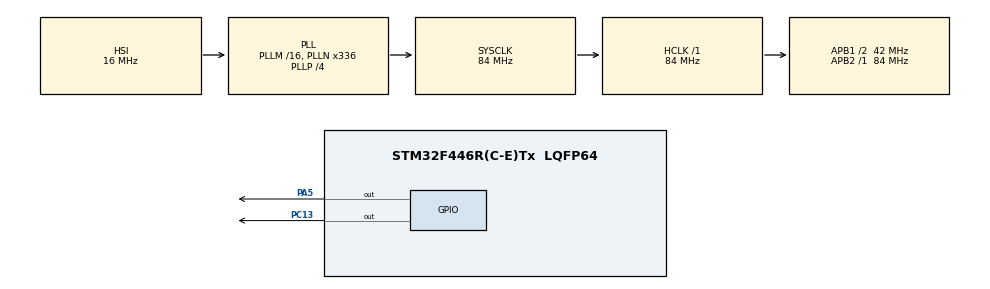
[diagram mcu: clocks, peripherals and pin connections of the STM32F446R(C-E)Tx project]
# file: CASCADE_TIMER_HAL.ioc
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Mcu.Family=STM32F4
Mcu.Name=STM32F446R(C-E)Tx
Mcu.Package=LQFP64
NVIC.PriorityGroup=NVIC_PRIORITYGROUP_0
NVIC.TIM4_IRQn=true\:0\:0\:false\:false\:true\:true\:true\:true
PA13.GPIO_Label=TMS
PA13.Mode=Serial_Wire
PA13.Signal=SYS_JTMS-SWDIO
PA14.GPIO_Label=TCK
PA14.Mode=Serial_Wire
PA14.Signal=SYS_JTCK-SWCLK
PA5.Signal=GPIO_Output
PB3.GPIO_Label=SWO
PB3.Signal=SYS_JTDO-SWO
PC13.Signal=GPIO_Output
PC14-OSC32_IN.Mode=LSE-External-Oscillator
PC14-OSC32_IN.Signal=RCC_OSC32_IN
PC15-OSC32_OUT.Mode=LSE-External-Oscillator
PC15-OSC32_OUT.Signal=RCC_OSC32_OUT
PH0-OSC_IN.Mode=HSE-External-Oscillator
PH0-OSC_IN.Signal=RCC_OSC_IN
PH1-OSC_OUT.Mode=HSE-External-Oscillator
PH1-OSC_OUT.Signal=RCC_OSC_OUT
ProjectManager.HeapSize=0x200
ProjectManager.StackSize=0x400
ProjectManager.TargetToolchain=STM32CubeIDE
RCC.48MHZClocksFreq_Value=84000000
RCC.AHBFreq_Value=84000000
RCC.APB1CLKDivider=RCC_HCLK_DIV2
RCC.APB1Freq_Value=42000000
RCC.APB1TimFreq_Value=84000000
RCC.APB2Freq_Value=84000000
RCC.APB2TimFreq_Value=84000000
RCC.CortexFreq_Value=84000000
RCC.FLatency-AdvancedSettings=FLASH_LATENCY_2
RCC.HCLKFreq_Value=84000000
RCC.HSE_VALUE=8000000
RCC.HSI_VALUE=16000000
RCC.PLLN=336
RCC.PLLP=RCC_PLLP_DIV4
RCC.SYSCLKFreq_VALUE=84000000
RCC.SYSCLKSource=RCC_SYSCLKSOURCE_PLLCLK
RCC.USBFreq_Value=168000000
RCC.VCOOutputFreq_Value=336000000
TIM3.Period=999
TIM3.Prescaler=15999
TIM3.TIM_MasterOutputTrigger=TIM_TRGO_UPDATE
TIM3.TIM_MasterSlaveMode=TIM_MASTERSLAVEMODE_ENABLE
TIM4.AutoReloadPreload=TIM_AUTORELOAD_PRELOAD_DISABLE
TIM4.Period=9
TIM4.TIM_MasterSlaveMode=TIM_MASTERSLAVEMODE_ENABLE
VP_TIM3_VS_ClockSourceINT.Mode=Internal
VP_TIM4_VS_ClockSourceITR.Mode=TriggerSource_ITR2
VP_TIM4_VS_ControllerModeClock.Mode=Clock Mode
board=NUCLEO-F446RE

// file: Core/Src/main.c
/* USER CODE BEGIN Header */
/**
  ******************************************************************************
  * @file           : main.c
  * @brief          : Main program body
  ******************************************************************************
  * @attention
  *
  * Copyright (c) 2025 STMicroelectronics.
  * All rights reserved.
  *
  * This software is licensed under terms that can be found in the LICENSE file
  * in the root directory of this software component.
  * If no LICENSE file comes with this software, it is provided AS-IS.
  *
  ******************************************************************************
  */
/* USER CODE END Header */
#include "main.h"

TIM_HandleTypeDef htim3;
TIM_HandleTypeDef htim4;

void SystemClock_Config(void);
static void MX_GPIO_Init(void);
static void MX_TIM3_Init(void);
static void MX_TIM4_Init(void);

/* USER CODE BEGIN 0 */
void HAL_TIM_PeriodElapsedCallback(TIM_HandleTypeDef *htim)
{
    if (htim->Instance == TIM4)
    {
    	 HAL_GPIO_TogglePin(GPIOA, GPIO_PIN_5);
    }
}

/* USER CODE END 0 */

int main(void)
{

  /* MCU Configuration--------------------------------------------------------*/

  /* Reset of all peripherals, Initializes the Flash interface and the Systick. */
  HAL_Init();

  /* Configure the system clock */
  SystemClock_Config();

  /* Initialize all configured peripherals */
  MX_GPIO_Init();
  MX_TIM3_Init();
  MX_TIM4_Init();
  /* USER CODE BEGIN 2 */
  HAL_TIM_Base_Start(&htim3);
  HAL_Delay(1000);  // <-- Give time for TIM3 to generate TRGO
  HAL_TIM_Base_Start_IT(&htim4);
  /* USER CODE END 2 */

  /* Infinite loop */
  while (1)
  {

  }
}

void SystemClock_Config(void)
{
  RCC_OscInitTypeDef RCC_OscInitStruct = {0};
  RCC_ClkInitTypeDef RCC_ClkInitStruct = {0};

  /** Configure the main internal regulator output voltage
  */
  __HAL_RCC_PWR_CLK_ENABLE();
  __HAL_PWR_VOLTAGESCALING_CONFIG(PWR_REGULATOR_VOLTAGE_SCALE3);

  /** Initializes the RCC Oscillators according to the specified parameters
  * in the RCC_OscInitTypeDef structure.
  */
  RCC_OscInitStruct.OscillatorType = RCC_OSCILLATORTYPE_HSI;
  RCC_OscInitStruct.HSIState = RCC_HSI_ON;
  RCC_OscInitStruct.HSICalibrationValue = RCC_HSICALIBRATION_DEFAULT;
  RCC_OscInitStruct.PLL.PLLState = RCC_PLL_ON;
  RCC_OscInitStruct.PLL.PLLSource = RCC_PLLSOURCE_HSI;
  RCC_OscInitStruct.PLL.PLLM = 16;
  RCC_OscInitStruct.PLL.PLLN = 336;
  RCC_OscInitStruct.PLL.PLLP = RCC_PLLP_DIV4;
  RCC_OscInitStruct.PLL.PLLQ = 2;
  RCC_OscInitStruct.PLL.PLLR = 2;
  if (HAL_RCC_OscConfig(&RCC_OscInitStruct) != HAL_OK)
  {
    Error_Handler();
  }

  /** Initializes the CPU, AHB and APB buses clocks
  */
  RCC_ClkInitStruct.ClockType = RCC_CLOCKTYPE_HCLK|RCC_CLOCKTYPE_SYSCLK
                              |RCC_CLOCKTYPE_PCLK1|RCC_CLOCKTYPE_PCLK2;
  RCC_ClkInitStruct.SYSCLKSource = RCC_SYSCLKSOURCE_PLLCLK;
  RCC_ClkInitStruct.AHBCLKDivider = RCC_SYSCLK_DIV1;
  RCC_ClkInitStruct.APB1CLKDivider = RCC_HCLK_DIV2;
  RCC_ClkInitStruct.APB2CLKDivider = RCC_HCLK_DIV1;

  if (HAL_RCC_ClockConfig(&RCC_ClkInitStruct, FLASH_LATENCY_2) != HAL_OK)
  {
    Error_Handler();
  }
}

static void MX_TIM3_Init(void)
{

  TIM_ClockConfigTypeDef sClockSourceConfig = {0};
  TIM_MasterConfigTypeDef sMasterConfig = {0};

  htim3.Instance = TIM3;
  htim3.Init.Prescaler = 15999;
  htim3.Init.CounterMode = TIM_COUNTERMODE_UP;
  htim3.Init.Period = 999;
  htim3.Init.ClockDivision = TIM_CLOCKDIVISION_DIV1;
  htim3.Init.AutoReloadPreload = TIM_AUTORELOAD_PRELOAD_DISABLE;
  if (HAL_TIM_Base_Init(&htim3) != HAL_OK)
  {
    Error_Handler();
  }
  sClockSourceConfig.ClockSource = TIM_CLOCKSOURCE_INTERNAL;
  if (HAL_TIM_ConfigClockSource(&htim3, &sClockSourceConfig) != HAL_OK)
  {
    Error_Handler();
  }
  sMasterConfig.MasterOutputTrigger = TIM_TRGO_UPDATE;
  sMasterConfig.MasterSlaveMode = TIM_MASTERSLAVEMODE_ENABLE;
  if (HAL_TIMEx_MasterConfigSynchronization(&htim3, &sMasterConfig) != HAL_OK)
  {
    Error_Handler();
  }

}

static void MX_TIM4_Init(void)
{

  TIM_SlaveConfigTypeDef sSlaveConfig = {0};
  TIM_MasterConfigTypeDef sMasterConfig = {0};

  htim4.Instance = TIM4;
  htim4.Init.Prescaler = 0;
  htim4.Init.CounterMode = TIM_COUNTERMODE_UP;
  htim4.Init.Period = 9;
  htim4.Init.ClockDivision = TIM_CLOCKDIVISION_DIV1;
  htim4.Init.AutoReloadPreload = TIM_AUTORELOAD_PRELOAD_DISABLE;
  if (HAL_TIM_Base_Init(&htim4) != HAL_OK)
  {
    Error_Handler();
  }
  sSlaveConfig.SlaveMode = TIM_SLAVEMODE_EXTERNAL1;
  sSlaveConfig.InputTrigger = TIM_TS_ITR2;
  if (HAL_TIM_SlaveConfigSynchro(&htim4, &sSlaveConfig) != HAL_OK)
  {
    Error_Handler();
  }
  sMasterConfig.MasterOutputTrigger = TIM_TRGO_RESET;
  sMasterConfig.MasterSlaveMode = TIM_MASTERSLAVEMODE_ENABLE;
  if (HAL_TIMEx_MasterConfigSynchronization(&htim4, &sMasterConfig) != HAL_OK)
  {
    Error_Handler();
  }

}

static void MX_GPIO_Init(void)
{
  GPIO_InitTypeDef GPIO_InitStruct = {0};

  /* GPIO Ports Clock Enable */
  __HAL_RCC_GPIOC_CLK_ENABLE();
  __HAL_RCC_GPIOH_CLK_ENABLE();
  __HAL_RCC_GPIOA_CLK_ENABLE();
  __HAL_RCC_GPIOB_CLK_ENABLE();

  /*Configure GPIO pin Output Level */
  HAL_GPIO_WritePin(GPIOC, GPIO_PIN_13, GPIO_PIN_RESET);

  /*Configure GPIO pin Output Level */
  HAL_GPIO_WritePin(GPIOA, GPIO_PIN_5, GPIO_PIN_RESET);

  /*Configure GPIO pin : PC13 */
  GPIO_InitStruct.Pin = GPIO_PIN_13;
  GPIO_InitStruct.Mode = GPIO_MODE_OUTPUT_PP;
  GPIO_InitStruct.Pull = GPIO_NOPULL;
  GPIO_InitStruct.Speed = GPIO_SPEED_FREQ_LOW;
  HAL_GPIO_Init(GPIOC, &GPIO_InitStruct);

  /*Configure GPIO pin : PA5 */
  GPIO_InitStruct.Pin = GPIO_PIN_5;
  GPIO_InitStruct.Mode = GPIO_MODE_OUTPUT_PP;
  GPIO_InitStruct.Pull = GPIO_NOPULL;
  GPIO_InitStruct.Speed = GPIO_SPEED_FREQ_LOW;
  HAL_GPIO_Init(GPIOA, &GPIO_InitStruct);

}

void Error_Handler(void)
{
  __disable_irq();
  while (1)
  {
  }
}
